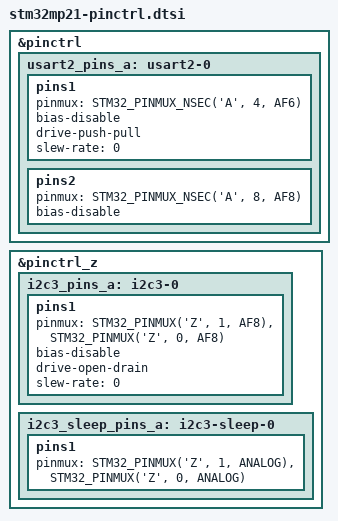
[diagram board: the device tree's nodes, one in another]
// SPDX-License-Identifier: (GPL-2.0-only OR BSD-3-Clause)
/*
 * Copyright (C) 2026, STMicroelectronics - All Rights Reserved
 * Author: Alexandre Torgue <alexandre.torgue@foss.st.com> for STMicroelectronics.
 */

#include <dt-bindings/pinctrl/stm32-pinfunc.h>

&pinctrl {
	usart2_pins_a: usart2-0 {
		pins1 {
			pinmux = <STM32_PINMUX_NSEC('A', 4, AF6)>; /* USART2_TX */
			bias-disable;
			drive-push-pull;
			slew-rate = <0>;
		};
		pins2 {
			pinmux = <STM32_PINMUX_NSEC('A', 8, AF8)>; /* USART2_RX */
			bias-disable;
		};
	};
};

&pinctrl_z {
	i2c3_pins_a: i2c3-0 {
		pins1 {
			pinmux = <STM32_PINMUX('Z', 1, AF8)>, /* I2C3_SCL */
				 <STM32_PINMUX('Z', 0, AF8)>; /* I2C3_SDA */
			bias-disable;
			drive-open-drain;
			slew-rate = <0>;
		};
	};

	i2c3_sleep_pins_a: i2c3-sleep-0 {
		pins1 {
			pinmux = <STM32_PINMUX('Z', 1, ANALOG)>, /* I2C3_SCL */
				 <STM32_PINMUX('Z', 0, ANALOG)>; /* I2C3_SDA */
		};
	};
};
